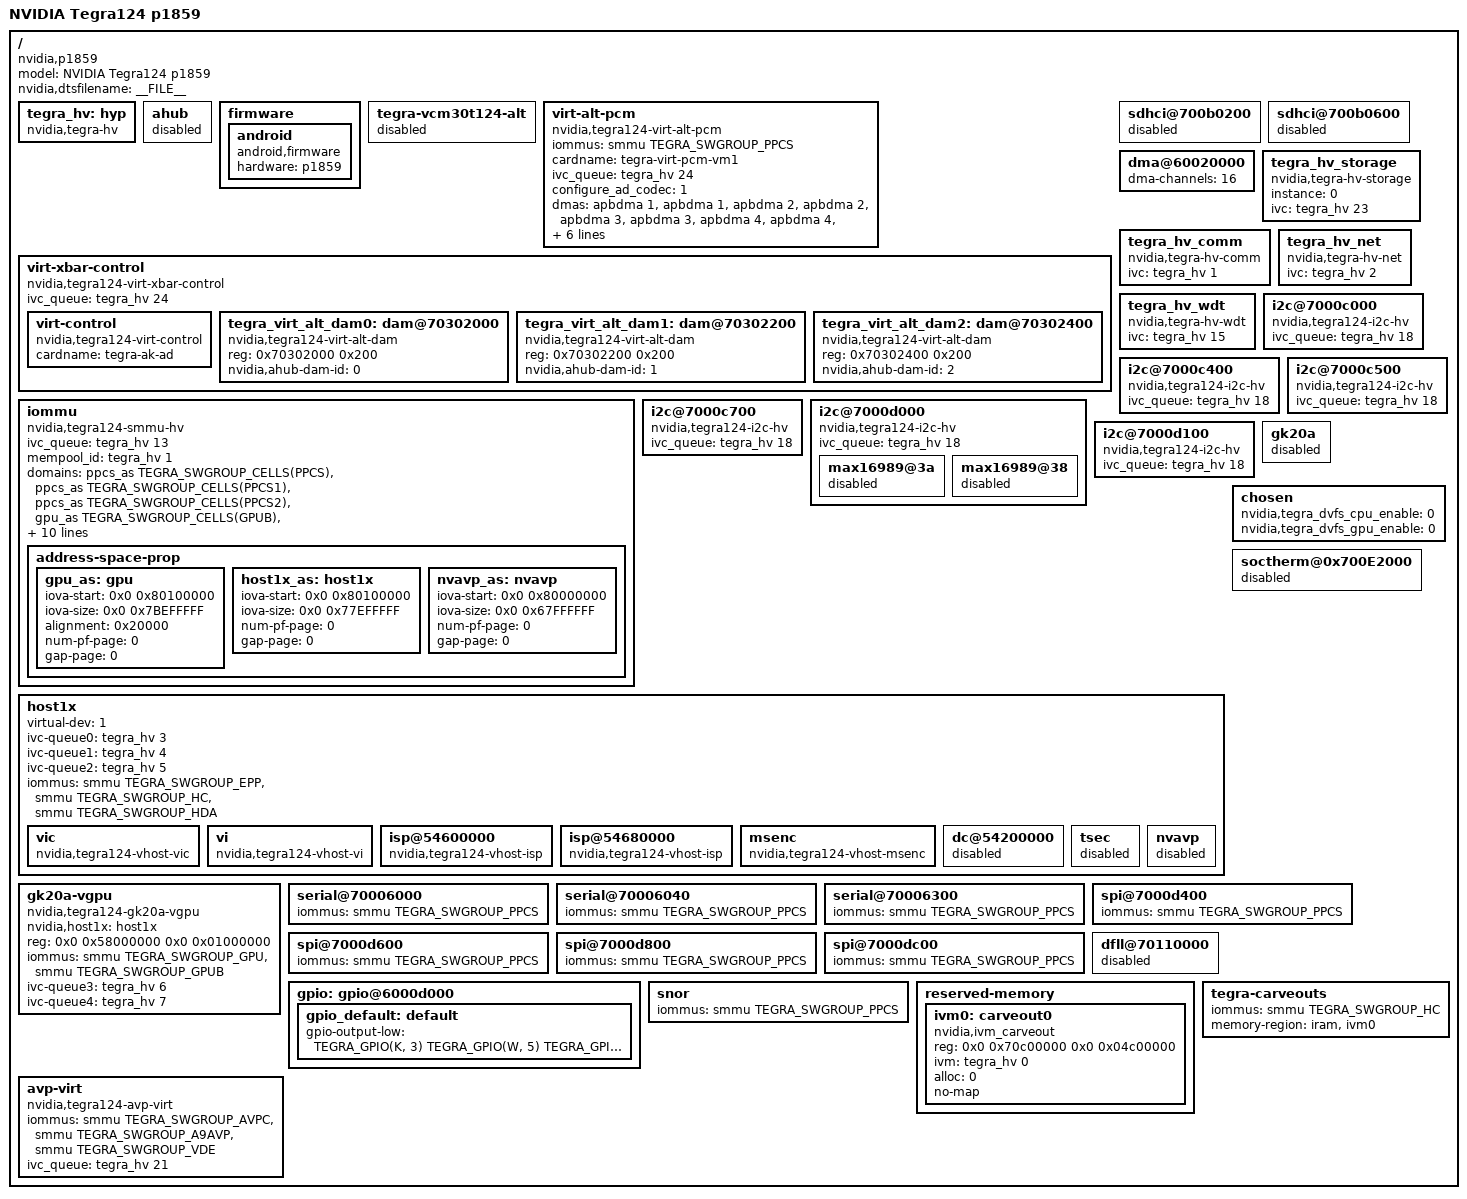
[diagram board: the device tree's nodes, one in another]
/*
 * arch/arm/boot/dts/tegra124-p1859-vm_1.dts
 *
 * Copyright (c) 2013-2015, NVIDIA CORPORATION.  All rights reserved.
 *
 * This program is free software; you can redistribute it and/or modify
 * it under the terms of the GNU General Public License as published by
 * the Free Software Foundation; version 2 of the License.
 *
 * This program is distributed in the hope that it will be useful, but WITHOUT
 * ANY WARRANTY; without even the implied warranty of MERCHANTABILITY or
 * FITNESS FOR A PARTICULAR PURPOSE.  See the GNU General Public License for
 * more details.
 *
 * You should have received a copy of the GNU General Public License along
 * with this program; if not, write to the Free Software Foundation, Inc.,
 * 51 Franklin Street, Fifth Floor, Boston, MA  02110-1301, USA.
 *
 */
 /dts-v1/;

/ {
	/* smmu and ivc drivers are called very early in the kernel init
	 * call sequence (core_initcall). smmu driver as such is a consumer
	 * of ivc and depends on it.
	 * Keeping the ivc node at the very top in the device tree ensures
	 * that probe for ivc is called before the smmu driver probe.
	 * Without this virtualized smmu driver probe will fail.
	 */
	tegra_hv: hyp {
		compatible = "nvidia,tegra-hv";
		status = "okay";
	};
};

#include "tegra124-p1859.dtsi"

/ {
	model = "NVIDIA Tegra124 p1859";
	compatible = "nvidia,p1859", "nvidia,tegra124";
	nvidia,dtsfilename = __FILE__;

	ahub {
		status = "disabled";
	};

	firmware {
		android {
			compatible = "android,firmware";
			hardware = "p1859";
		};
	};

	tegra-vcm30t124-alt {
		status = "disabled";
	};

	virt-alt-pcm {
		compatible = "nvidia,tegra124-virt-alt-pcm";
		iommus = < &smmu TEGRA_SWGROUP_PPCS >;
		status = "okay";
		cardname = "tegra-virt-pcm-vm1";
		ivc_queue = <&tegra_hv 24>;
		configure_ad_codec = <1>;
		dmas =	<&apbdma 1>, <&apbdma 1>, <&apbdma 2>, <&apbdma 2>,
				 <&apbdma 3>, <&apbdma 3>, <&apbdma 4>, <&apbdma 4>,
				 <&apbdma 6>, <&apbdma 6>, <&apbdma 7>, <&apbdma 7>,
				 <&apbdma 12>, <&apbdma 12>, <&apbdma 13>, <&apbdma 13>,
				 <&apbdma 14>, <&apbdma 14>, <&apbdma 29>, <&apbdma 29>;
		dma-names =	"rx0", "tx0", "rx1", "tx1", "rx2", "tx2",
				"rx3", "tx3", "rx4", "tx4", "rx5", "tx5",
				"rx6", "tx6", "rx7", "tx7", "rx8", "tx8",
				"rx9", "tx9";
		/*
		** The default asound.conf file for the VMs expect the apbif channels
		** to be (0, 1, 2, 3) if the apbif_group_id is set to 1 and
		** (4, 5, 6, 7, 8, 9) if the apbif_group_id is set to 2. If random apbif
		** channels has to be assigned, corresponding change has to be made in
		** the asound.conf file also.
		*/
		apbif_group_id = <1>;
		apbif_ch_num = <4>;
		apbif_ch_list = <0>, <1>, <2>, <3>;
	};

	virt-xbar-control {
		compatible = "nvidia,tegra124-virt-xbar-control";
		status = "okay";
		ivc_queue = <&tegra_hv 24>;
		#address-cells = <1>;
		#size-cells = <1>;

		ranges = <0x70300000 0x0 0x70300000 0x00010000>;


		virt-control {
			compatible = "nvidia,tegra124-virt-control";
			cardname = "tegra-ak-ad";
			status = "okay";
		};

		tegra_virt_alt_dam0: dam@70302000 {
			reg = <0x70302000 0x200>;
			compatible = "nvidia,tegra124-virt-alt-dam";
			nvidia,ahub-dam-id = <0>;
			status = "okay";
		};

		tegra_virt_alt_dam1: dam@70302200 {
			reg = <0x70302200 0x200>;
			compatible = "nvidia,tegra124-virt-alt-dam";
			nvidia,ahub-dam-id = <1>;
			status = "okay";
		};

		tegra_virt_alt_dam2: dam@70302400 {
			reg = <0x70302400 0x200>;
			compatible = "nvidia,tegra124-virt-alt-dam";
			nvidia,ahub-dam-id = <2>;
			status = "okay";
		};
	};

	sdhci@700b0200 {
		status = "disabled";
	};

	sdhci@700b0600 {
		status = "disabled";
	};

	dma@60020000 {
		dma-channels = <16>;
		status = "okay";
	};

	tegra_hv_storage {
		compatible = "nvidia,tegra-hv-storage";
		status = "okay";
		instance = <0>;
		ivc = <&tegra_hv 23>;
	};

	tegra_hv_comm {
		compatible = "nvidia,tegra-hv-comm";
		status = "okay";
		ivc = <&tegra_hv 1>;
	};

	tegra_hv_net {
		compatible = "nvidia,tegra-hv-net";
		status = "okay";
		ivc = <&tegra_hv 2>;
	};

	tegra_hv_wdt {
		compatible = "nvidia,tegra-hv-wdt";
		status = "okay";
		ivc = <&tegra_hv 15>;
	};

	iommu {
		compatible = "nvidia,tegra124-smmu-hv";
		ivc_queue = <&tegra_hv 13>;
		mempool_id = <&tegra_hv 1>;

		domains = <
			&ppcs_as TEGRA_SWGROUP_CELLS(PPCS)
			&ppcs_as TEGRA_SWGROUP_CELLS(PPCS1)
			&ppcs_as TEGRA_SWGROUP_CELLS(PPCS2)
			&gpu_as TEGRA_SWGROUP_CELLS(GPUB)
			&dc_as TEGRA_SWGROUP_CELLS2(DC, DC12)
			&dc_as TEGRA_SWGROUP_CELLS(DCB)
			&common_as TEGRA_SWGROUP_CELLS(AFI)
			&common_as TEGRA_SWGROUP_CELLS(SDMMC1A)
			&common_as TEGRA_SWGROUP_CELLS(SDMMC2A)
			&common_as TEGRA_SWGROUP_CELLS(SDMMC3A)
			&common_as TEGRA_SWGROUP_CELLS(SDMMC4A)
			&host1x_as TEGRA_SWGROUP_CELLS9(EPP, HC, HDA, VI, ISP, ISP2B, VIC, MSENC, TSEC)
			&nvavp_as TEGRA_SWGROUP_CELLS3(AVPC, A9AVP, VDE)
			&common_as 0xFFFFFFFF 0xFFFFFFFF>;

		address-space-prop {
			gpu_as: gpu {
				iova-start = <0x0 0x80100000>;
				iova-size = <0x0 0x7BEFFFFF>;
				alignment = <0x20000>;
				num-pf-page = <0>;
				gap-page = <0>;
			};

			host1x_as: host1x {
				iova-start = <0x0 0x80100000>;
				iova-size = <0x0 0x77EFFFFF>;
				num-pf-page = <0>;
				gap-page = <0>;
			};

			nvavp_as: nvavp {
				iova-start = <0x0 0x80000000>;
				iova-size = <0x0 0x67FFFFFF>;
				num-pf-page = <0>;
				gap-page = <0>;
			};
		};
	};

	i2c@7000c000 {
		compatible = "nvidia,tegra124-i2c-hv";
		ivc_queue = <&tegra_hv 18>;
	};

	i2c@7000c400 {
		compatible = "nvidia,tegra124-i2c-hv";
		ivc_queue = <&tegra_hv 18>;
	};

	i2c@7000c500 {
		compatible = "nvidia,tegra124-i2c-hv";
		ivc_queue = <&tegra_hv 18>;
	};

	i2c@7000c700 {
		compatible = "nvidia,tegra124-i2c-hv";
		ivc_queue = <&tegra_hv 18>;
	};

	i2c@7000d000 {
		compatible = "nvidia,tegra124-i2c-hv";
		ivc_queue = <&tegra_hv 18>;
		status = "okay";

		max16989@3a {
			status = "disabled";
		};

		max16989@38 {
			status = "disabled";
		};
	};

	i2c@7000d100 {
		compatible = "nvidia,tegra124-i2c-hv";
		ivc_queue = <&tegra_hv 18>;
	};

	host1x {
		virtual-dev = <1>;

		ivc-queue0 = <&tegra_hv 3>;
		ivc-queue1 = <&tegra_hv 4>;
		ivc-queue2 = <&tegra_hv 5>;

		iommus = <&smmu TEGRA_SWGROUP_EPP>,
			<&smmu TEGRA_SWGROUP_HC>,
			<&smmu TEGRA_SWGROUP_HDA>;

		vic {
			compatible = "nvidia,tegra124-vhost-vic";
		};

		vi {
			compatible = "nvidia,tegra124-vhost-vi";
		};

		isp@54600000 {
			compatible = "nvidia,tegra124-vhost-isp";
		};

		isp@54680000 {
			compatible = "nvidia,tegra124-vhost-isp";
		};

		msenc {
			compatible = "nvidia,tegra124-vhost-msenc";
		};

		/delete-node/ dpaux;
		/delete-node/ sor;

		/* tegradc.0 */
		dc@54200000 {
			status = "disabled";
		};

		tsec {
			status = "disabled";
		};

		nvavp {
			status = "disabled";
		};
	};

	gk20a {
		status = "disabled";
	};

	gk20a-vgpu {
		compatible = "nvidia,tegra124-gk20a-vgpu";
		nvidia,host1x = <&host1x>;
		reg = <0x0 0x58000000 0x0 0x01000000>;
		iommus = <&smmu TEGRA_SWGROUP_GPU &smmu TEGRA_SWGROUP_GPUB>;

		ivc-queue3 = <&tegra_hv 6>;
		ivc-queue4 = <&tegra_hv 7>;
	};

	chosen {
		nvidia,tegra_dvfs_cpu_enable = <0>;
		nvidia,tegra_dvfs_gpu_enable = <0>;
	};

	soctherm@0x700E2000 {
		status = "disabled";
	};

	serial@70006000 {
		iommus = <&smmu TEGRA_SWGROUP_PPCS>;
		status = "okay";
	};

	serial@70006040 {
		iommus = <&smmu TEGRA_SWGROUP_PPCS>;
		status = "okay";
	};

	serial@70006300 {
		iommus = <&smmu TEGRA_SWGROUP_PPCS>;
		status = "okay";
	};

	spi@7000d400 {
		iommus = <&smmu TEGRA_SWGROUP_PPCS>;
		status = "okay";
	};

	spi@7000d600 {
		iommus = <&smmu TEGRA_SWGROUP_PPCS>;
		status = "okay";
	};

	spi@7000d800 {
		iommus = <&smmu TEGRA_SWGROUP_PPCS>;
		status = "okay";
	};

	spi@7000dc00 {
		iommus = <&smmu TEGRA_SWGROUP_PPCS>;
		status = "okay";
	};

	dfll@70110000 {
		status = "disabled";
	};

	gpio: gpio@6000d000 {
		gpio_default: default {
		gpio-output-low = <TEGRA_GPIO(K, 3)
				TEGRA_GPIO(W, 5)
				TEGRA_GPIO(R, 3)
				TEGRA_GPIO(R, 5)
				TEGRA_GPIO(R, 6)>;
		};
	};

	snor {
		iommus = <&smmu TEGRA_SWGROUP_PPCS>;
		status = "okay";
	};

	reserved-memory {
		ivm0: carveout0 {
			compatible = "nvidia,ivm_carveout";
			reg = <0x0 0x70c00000 0x0 0x04c00000>;
			ivm = <&tegra_hv 0>;
			alloc = <0>;
			no-map;
		};
	};

	tegra-carveouts {
		iommus = <&smmu TEGRA_SWGROUP_HC>;
		status = "okay";
		memory-region = <&iram &ivm0>;
	};

	avp-virt {
		compatible = "nvidia,tegra124-avp-virt";
		iommus = <&smmu TEGRA_SWGROUP_AVPC>,
			 <&smmu TEGRA_SWGROUP_A9AVP>,
			 <&smmu TEGRA_SWGROUP_VDE>;
		ivc_queue = <&tegra_hv 21>;
	};
};
